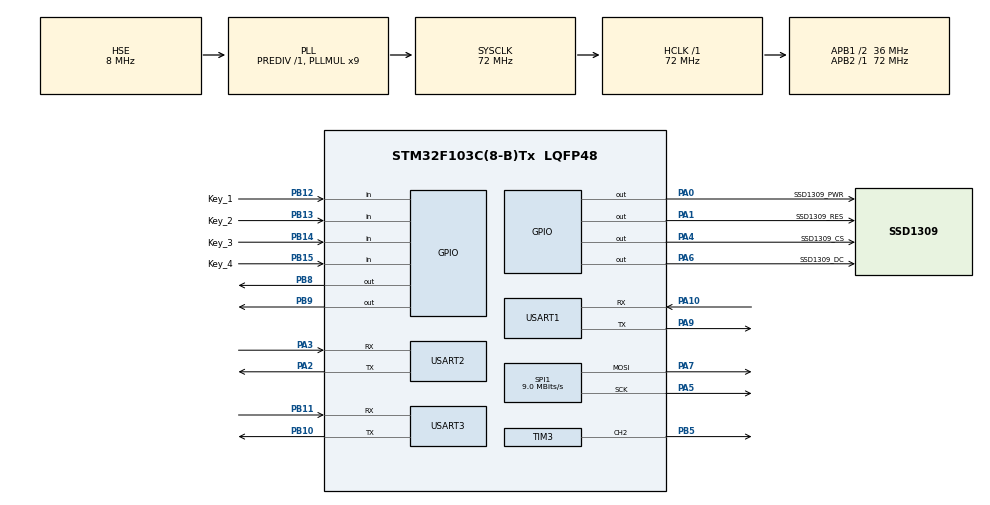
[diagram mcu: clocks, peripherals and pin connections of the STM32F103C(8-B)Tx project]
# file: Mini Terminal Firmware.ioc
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Dma.Request0=SPI1_TX
Dma.SPI1_TX.0.Direction=DMA_MEMORY_TO_PERIPH
Dma.SPI1_TX.0.Instance=DMA1_Channel3
Dma.SPI1_TX.0.MemDataAlignment=DMA_MDATAALIGN_BYTE
Dma.SPI1_TX.0.MemInc=DMA_MINC_ENABLE
Dma.SPI1_TX.0.Mode=DMA_NORMAL
Dma.SPI1_TX.0.PeriphDataAlignment=DMA_PDATAALIGN_BYTE
Dma.SPI1_TX.0.PeriphInc=DMA_PINC_DISABLE
Dma.SPI1_TX.0.Priority=DMA_PRIORITY_LOW
Mcu.Family=STM32F1
Mcu.Name=STM32F103C(8-B)Tx
Mcu.Package=LQFP48
NVIC.DMA1_Channel3_IRQn=true\:0\:0\:false\:false\:true\:false\:true\:true
NVIC.PriorityGroup=NVIC_PRIORITYGROUP_4
NVIC.SPI1_IRQn=true\:0\:0\:false\:false\:true\:true\:true\:true
NVIC.TIM4_IRQn=true\:0\:0\:false\:false\:true\:true\:true\:true
PA0-WKUP.GPIO_Label=SSD1309_PWR
PA0-WKUP.Signal=GPIO_Output
PA1.GPIO_Label=SSD1309_RES
PA1.Signal=GPIO_Output
PA10.Mode=Asynchronous
PA10.Signal=USART1_RX
PA13.Mode=Serial_Wire
PA13.Signal=SYS_JTMS-SWDIO
PA14.Mode=Serial_Wire
PA14.Signal=SYS_JTCK-SWCLK
PA2.Mode=Asynchronous
PA2.Signal=USART2_TX
PA3.Mode=Asynchronous
PA3.Signal=USART2_RX
PA4.GPIO_Label=SSD1309_CS
PA4.Signal=GPIO_Output
PA5.GPIO_Speed=GPIO_SPEED_FREQ_LOW
PA5.Mode=TX_Only_Simplex_Unidirect_Master
PA5.Signal=SPI1_SCK
PA6.GPIO_Label=SSD1309_DC
PA6.Signal=GPIO_Output
PA7.GPIO_Speed=GPIO_SPEED_FREQ_LOW
PA7.Mode=TX_Only_Simplex_Unidirect_Master
PA7.Signal=SPI1_MOSI
PA9.Mode=Asynchronous
PA9.Signal=USART1_TX
PB10.Mode=Asynchronous
PB10.Signal=USART3_TX
PB11.Mode=Asynchronous
PB11.Signal=USART3_RX
PB12.GPIO_Label=Key_1
PB12.Signal=GPIO_Input
PB13.GPIO_Label=Key_2
PB13.Signal=GPIO_Input
PB14.GPIO_Label=Key_3
PB14.Signal=GPIO_Input
PB15.GPIO_Label=Key_4
PB15.Signal=GPIO_Input
PB5.Signal=S_TIM3_CH2
PB8.Signal=GPIO_Output
PB9.Signal=GPIO_Output
PD0-OSC_IN.Mode=HSE-External-Oscillator
PD0-OSC_IN.Signal=RCC_OSC_IN
PD1-OSC_OUT.Mode=HSE-External-Oscillator
PD1-OSC_OUT.Signal=RCC_OSC_OUT
ProjectManager.HeapSize=0x200
ProjectManager.StackSize=0x400
ProjectManager.TargetToolchain=STM32CubeIDE
RCC.AHBFreq_Value=72000000
RCC.APB1CLKDivider=RCC_HCLK_DIV2
RCC.APB1Freq_Value=36000000
RCC.APB1TimFreq_Value=72000000
RCC.APB2Freq_Value=72000000
RCC.APB2TimFreq_Value=72000000
RCC.EnbaleCSS=true
RCC.HCLKFreq_Value=72000000
RCC.PLLMUL=RCC_PLL_MUL9
RCC.PLLSourceVirtual=RCC_PLLSOURCE_HSE
RCC.SYSCLKFreq_VALUE=72000000
RCC.SYSCLKSource=RCC_SYSCLKSOURCE_PLLCLK
RCC.USBFreq_Value=48000000
RCC.USBPrescaler=RCC_USBCLKSOURCE_PLL_DIV1_5
SH.S_TIM3_CH2.0=TIM3_CH2,PWM Generation2 CH2
SPI1.BaudRatePrescaler=SPI_BAUDRATEPRESCALER_8
SPI1.CalculateBaudRate=9.0 MBits/s
SPI1.Direction=SPI_DIRECTION_2LINES
SPI1.Mode=SPI_MODE_MASTER
SPI1.VirtualType=VM_MASTER
TIM3.Channel-PWM\ Generation2\ CH2=TIM_CHANNEL_2
TIM4.Period=719
TIM4.Prescaler=9
USART1.VirtualMode=VM_ASYNC
USART2.VirtualMode=VM_ASYNC
USART3.VirtualMode=VM_ASYNC
VP_TIM4_VS_ClockSourceINT.Mode=Internal
board=custom

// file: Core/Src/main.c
/* USER CODE BEGIN Header */
/**
 ******************************************************************************
 * @file           : main.c
 * @brief          : Main program body
 ******************************************************************************
 * @attention
 *
 * Copyright (c) 2024 STMicroelectronics.
 * All rights reserved.
 *
 * This software is licensed under terms that can be found in the LICENSE file
 * in the root directory of this software component.
 * If no LICENSE file comes with this software, it is provided AS-IS.
 *
 ******************************************************************************
 */
/* USER CODE END Header */
#include "main.h"
#include "dma.h"
#include "spi.h"
#include "tim.h"
#include "usart.h"
#include "gpio.h"

/* USER CODE BEGIN Includes */
#include <stdlib.h>
/* USER CODE END Includes */

void SystemClock_Config(void);

int main(void)
{

	/* MCU Configuration--------------------------------------------------------*/

	/* Reset of all peripherals, Initializes the Flash interface and the Systick. */
	HAL_Init();

	/* Configure the system clock */
	SystemClock_Config();

	/* Initialize all configured peripherals */
	MX_GPIO_Init();
	MX_DMA_Init();
	MX_SPI1_Init();
	MX_TIM3_Init();
	MX_USART1_UART_Init();
	MX_USART2_UART_Init();
	MX_USART3_UART_Init();
	MX_TIM4_Init();
	/* USER CODE BEGIN 2 */
	SSD1309_Init();

	uint8_t FB_Data[SSD1309_ResX * SSD1309_ResY / GBW_PixelPerData] = { 0 };
	GBW_Instance_t Display;
	GBW_Init(&Display, 	SSD1309_ResX, SSD1309_ResY, FB_Data, sizeof(FB_Data), 10, GUI_Draw, (uint32_t (*)(uint8_t*, uint32_t)) SSD1309_FlushFrame, (uint32_t (*)(void)) SSD1309_CheckReady);
	/* USER CODE END 2 */

	/* Infinite loop */
	/* USER CODE BEGIN WHILE */
	while (1)
	{
		GBW_LoopHandler(&Display);
		/* USER CODE END WHILE */

	}
}

void SystemClock_Config(void)
{
	RCC_OscInitTypeDef RCC_OscInitStruct =
	{ 0 };
	RCC_ClkInitTypeDef RCC_ClkInitStruct =
	{ 0 };

	/** Initializes the RCC Oscillators according to the specified parameters
	 * in the RCC_OscInitTypeDef structure.
	 */
	RCC_OscInitStruct.OscillatorType = RCC_OSCILLATORTYPE_HSE;
	RCC_OscInitStruct.HSEState = RCC_HSE_ON;
	RCC_OscInitStruct.HSEPredivValue = RCC_HSE_PREDIV_DIV1;
	RCC_OscInitStruct.HSIState = RCC_HSI_ON;
	RCC_OscInitStruct.PLL.PLLState = RCC_PLL_ON;
	RCC_OscInitStruct.PLL.PLLSource = RCC_PLLSOURCE_HSE;
	RCC_OscInitStruct.PLL.PLLMUL = RCC_PLL_MUL9;
	if (HAL_RCC_OscConfig(&RCC_OscInitStruct) != HAL_OK)
	{
		Error_Handler();
	}

	/** Initializes the CPU, AHB and APB buses clocks
	 */
	RCC_ClkInitStruct.ClockType = RCC_CLOCKTYPE_HCLK | RCC_CLOCKTYPE_SYSCLK
			| RCC_CLOCKTYPE_PCLK1 | RCC_CLOCKTYPE_PCLK2;
	RCC_ClkInitStruct.SYSCLKSource = RCC_SYSCLKSOURCE_PLLCLK;
	RCC_ClkInitStruct.AHBCLKDivider = RCC_SYSCLK_DIV1;
	RCC_ClkInitStruct.APB1CLKDivider = RCC_HCLK_DIV2;
	RCC_ClkInitStruct.APB2CLKDivider = RCC_HCLK_DIV1;

	if (HAL_RCC_ClockConfig(&RCC_ClkInitStruct, FLASH_LATENCY_2) != HAL_OK)
	{
		Error_Handler();
	}

	/** Enables the Clock Security System
	 */
	HAL_RCC_EnableCSS();
}

/* USER CODE BEGIN 4 */
void HAL_SPI_TxCpltCallback(SPI_HandleTypeDef *hspi)
{
	SSD1309_TsfrCpltHandler();
}
/* USER CODE END 4 */

void Error_Handler(void)
{
	__disable_irq();
	while (1)
	{
	}
}
